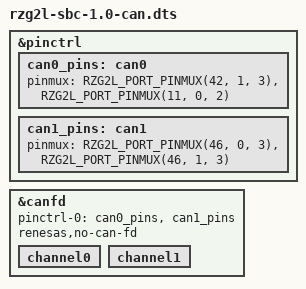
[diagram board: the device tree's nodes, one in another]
// SPDX-License-Identifier: GPL-2.0+
/*
 * Copyright (C) 2023 Renesas Electronics Corporation
 */

/dts-v1/;
/plugin/;

#include <dt-bindings/pinctrl/rzg2l-pinctrl.h>

/* 40-pin extended GPIO, expanded into UART, SPI, I2C, PWM and other interfaces */
&pinctrl {
	can0_pins: can0 {
		pinmux = <RZG2L_PORT_PINMUX(42, 1, 3)>, /* TX */
			 <RZG2L_PORT_PINMUX(11, 0, 2)>; /* RX */
	};

	can1_pins: can1 {
		pinmux = <RZG2L_PORT_PINMUX(46, 0, 3)>, /* TX */
			 <RZG2L_PORT_PINMUX(46, 1, 3)>; /* RX */
	};
};

&canfd {
	pinctrl-0 = <&can0_pins>, <&can1_pins>;
	pinctrl-names = "default";
	status = "okay";

	/* Default set as Classical CAN(CAN 2.0) mode, remove to enable CAN FD mode */
	renesas,no-can-fd;

	/* CAN on 40pin header without transceiver */
	channel0 {
		status = "okay";
	};

	/* CAN on J18 with transceiver */
	channel1 {
		status = "okay";
	};
};
